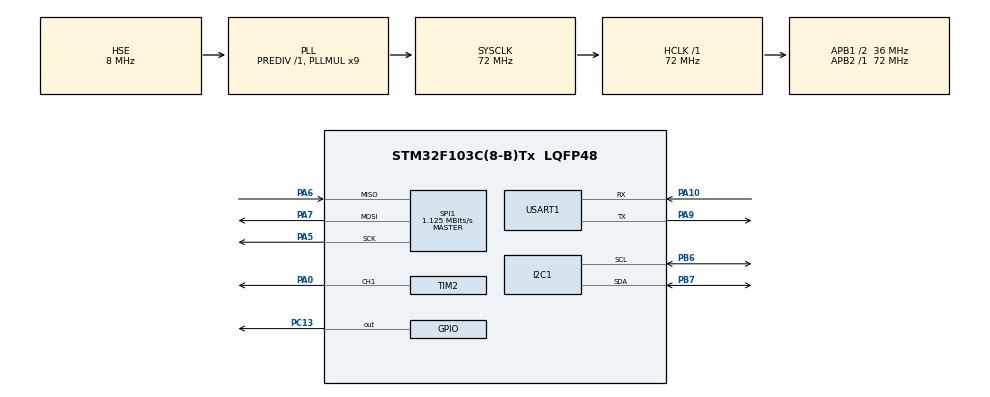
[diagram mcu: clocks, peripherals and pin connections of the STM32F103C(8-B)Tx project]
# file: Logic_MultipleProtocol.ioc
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Mcu.Family=STM32F1
Mcu.Name=STM32F103C(8-B)Tx
Mcu.Package=LQFP48
NVIC.I2C1_ER_IRQn=true\:0\:0\:false\:false\:true\:true\:true\:true
NVIC.I2C1_EV_IRQn=true\:0\:0\:false\:false\:true\:true\:true\:true
NVIC.PriorityGroup=NVIC_PRIORITYGROUP_4
NVIC.SPI1_IRQn=true\:0\:0\:false\:false\:true\:true\:true\:true
NVIC.USART1_IRQn=true\:0\:0\:false\:false\:true\:true\:true\:true
PA0-WKUP.Signal=S_TIM2_CH1_ETR
PA10.Mode=Asynchronous
PA10.Signal=USART1_RX
PA13.Mode=Serial_Wire
PA13.Signal=SYS_JTMS-SWDIO
PA14.Mode=Serial_Wire
PA14.Signal=SYS_JTCK-SWCLK
PA5.Mode=Full_Duplex_Master
PA5.Signal=SPI1_SCK
PA6.Mode=Full_Duplex_Master
PA6.Signal=SPI1_MISO
PA7.Mode=Full_Duplex_Master
PA7.Signal=SPI1_MOSI
PA9.Mode=Asynchronous
PA9.Signal=USART1_TX
PB6.Mode=I2C
PB6.Signal=I2C1_SCL
PB7.Mode=I2C
PB7.Signal=I2C1_SDA
PC13-TAMPER-RTC.PinState=GPIO_PIN_SET
PC13-TAMPER-RTC.Signal=GPIO_Output
PD0-OSC_IN.Mode=HSE-External-Oscillator
PD0-OSC_IN.Signal=RCC_OSC_IN
PD1-OSC_OUT.Mode=HSE-External-Oscillator
PD1-OSC_OUT.Signal=RCC_OSC_OUT
ProjectManager.HeapSize=0x200
ProjectManager.StackSize=0x400
ProjectManager.TargetToolchain=MDK-ARM V5.32
RCC.AHBFreq_Value=72000000
RCC.APB1CLKDivider=RCC_HCLK_DIV2
RCC.APB1Freq_Value=36000000
RCC.APB1TimFreq_Value=72000000
RCC.APB2Freq_Value=72000000
RCC.APB2TimFreq_Value=72000000
RCC.EnbaleCSS=true
RCC.HCLKFreq_Value=72000000
RCC.PLLMUL=RCC_PLL_MUL9
RCC.PLLSourceVirtual=RCC_PLLSOURCE_HSE
RCC.SYSCLKFreq_VALUE=72000000
RCC.SYSCLKSource=RCC_SYSCLKSOURCE_PLLCLK
RCC.USBFreq_Value=72000000
SH.S_TIM2_CH1_ETR.0=TIM2_CH1,PWM Generation1 CH1
SPI1.BaudRatePrescaler=SPI_BAUDRATEPRESCALER_64
SPI1.CalculateBaudRate=1.125 MBits/s
SPI1.Direction=SPI_DIRECTION_2LINES
SPI1.Mode=SPI_MODE_MASTER
SPI1.VirtualType=VM_MASTER
TIM2.Channel-PWM\ Generation1\ CH1=TIM_CHANNEL_1
TIM2.Period=999
TIM2.Prescaler=71
TIM2.Pulse-PWM\ Generation1\ CH1=500
USART1.VirtualMode=VM_ASYNC
board=custom

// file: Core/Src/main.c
/* USER CODE BEGIN Header */
/**
  ******************************************************************************
  * @file           : main.c
  * @brief          : Main program body
  ******************************************************************************
  * @attention
  *
  * Copyright (c) 2025 STMicroelectronics.
  * All rights reserved.
  *
  * This software is licensed under terms that can be found in the LICENSE file
  * in the root directory of this software component.
  * If no LICENSE file comes with this software, it is provided AS-IS.
  *
  ******************************************************************************
  */
/* USER CODE END Header */
#include "main.h"
#include "i2c.h"
#include "spi.h"
#include "tim.h"
#include "usart.h"
#include "gpio.h"

/* USER CODE BEGIN PV */

// volatile uint8_t uart_ready = 1; // 串口发送完成标志

/* USER CODE END PV */

void SystemClock_Config(void);
/* USER CODE BEGIN PFP */

// void HAL_GPIO_ToggleTest(void) {
//     // GPIO 翻转，1kHz方波
//     HAL_GPIO_TogglePin(GPIOB, GPIO_PIN_4);
//     HAL_Delay(1); // 1ms，得到约500Hz，改成500us可得1kHz
// }
void UART_Test(void) {
    char msg[] = "Hello LA!\r\n";
    HAL_UART_Transmit(&huart1, (uint8_t*)msg, sizeof(msg)-1, 100);
    // HAL_UART_Transmit_IT(&huart1, (uint8_t*)msg, sizeof(msg)-1);
}
// void UART_Test_IT(void) {
//     char msg[] = "Hello LA!\r\n";
//     if (uart_ready) {
//         uart_ready = 0;
//         HAL_UART_Transmit_IT(&huart1, (uint8_t*)msg, sizeof(msg)-1);
//     }
// }
// void I2C_Test(void) {
//     uint8_t data[2] = {0x12, 0x34};
//     // HAL_I2C_Master_Transmit(&hi2c1, 0x50<<1, data, 2, 100);
//     HAL_I2C_Master_Transmit_IT(&hi2c1, 0x50<<1, data, 2);
// }
// void SPI_Test(void) {
//     uint8_t data[4] = {0xAA, 0x55, 0xFF, 0x00};
//     HAL_SPI_Transmit(&hspi1, data, 4, 100);
// }

/* USER CODE END PFP */

int main(void)
{

  /* MCU Configuration--------------------------------------------------------*/

  /* Reset of all peripherals, Initializes the Flash interface and the Systick. */
  HAL_Init();

  /* Configure the system clock */
  SystemClock_Config();

  /* Initialize all configured peripherals */
  MX_GPIO_Init();
  MX_I2C1_Init();
  MX_SPI1_Init();
  MX_TIM2_Init();
  MX_USART1_UART_Init();
  /* USER CODE BEGIN 2 */

  // uint8_t data[2] = {0xAB, 0xCD};

  HAL_TIM_PWM_Start(&htim2, TIM_CHANNEL_1);

  /* USER CODE END 2 */

  /* Infinite loop */
  /* USER CODE BEGIN WHILE */
  while (1)
  {
// HAL_GPIO_TogglePin(GPIOC, GPIO_PIN_13);
// HAL_Delay(100);

    // HAL_GPIO_ToggleTest(); // 方波
    // UART_Test_IT();
    UART_Test();          // 串口数据
    HAL_Delay(1);      // 串口数据
    // I2C_Test();            // I2C总线波形
    // SPI_Test();            // SPI总线波形
    /* USER CODE END WHILE */

  }
}

void SystemClock_Config(void)
{
  RCC_OscInitTypeDef RCC_OscInitStruct = {0};
  RCC_ClkInitTypeDef RCC_ClkInitStruct = {0};

  /** Initializes the RCC Oscillators according to the specified parameters
  * in the RCC_OscInitTypeDef structure.
  */
  RCC_OscInitStruct.OscillatorType = RCC_OSCILLATORTYPE_HSE;
  RCC_OscInitStruct.HSEState = RCC_HSE_ON;
  RCC_OscInitStruct.HSEPredivValue = RCC_HSE_PREDIV_DIV1;
  RCC_OscInitStruct.HSIState = RCC_HSI_ON;
  RCC_OscInitStruct.PLL.PLLState = RCC_PLL_ON;
  RCC_OscInitStruct.PLL.PLLSource = RCC_PLLSOURCE_HSE;
  RCC_OscInitStruct.PLL.PLLMUL = RCC_PLL_MUL9;
  if (HAL_RCC_OscConfig(&RCC_OscInitStruct) != HAL_OK)
  {
    Error_Handler();
  }

  /** Initializes the CPU, AHB and APB buses clocks
  */
  RCC_ClkInitStruct.ClockType = RCC_CLOCKTYPE_HCLK|RCC_CLOCKTYPE_SYSCLK
                              |RCC_CLOCKTYPE_PCLK1|RCC_CLOCKTYPE_PCLK2;
  RCC_ClkInitStruct.SYSCLKSource = RCC_SYSCLKSOURCE_PLLCLK;
  RCC_ClkInitStruct.AHBCLKDivider = RCC_SYSCLK_DIV1;
  RCC_ClkInitStruct.APB1CLKDivider = RCC_HCLK_DIV2;
  RCC_ClkInitStruct.APB2CLKDivider = RCC_HCLK_DIV1;

  if (HAL_RCC_ClockConfig(&RCC_ClkInitStruct, FLASH_LATENCY_2) != HAL_OK)
  {
    Error_Handler();
  }

  /** Enables the Clock Security System
  */
  HAL_RCC_EnableCSS();
}

/* USER CODE BEGIN 4 */

// void HAL_UART_TxCpltCallback(UART_HandleTypeDef *huart) {
//     if (huart->Instance == USART1) {
//         uart_ready = 1;
//     }
// }

/* USER CODE END 4 */

void Error_Handler(void)
{
  __disable_irq();
  while (1)
  {
  }
}
